VERSION ""

NS_ :

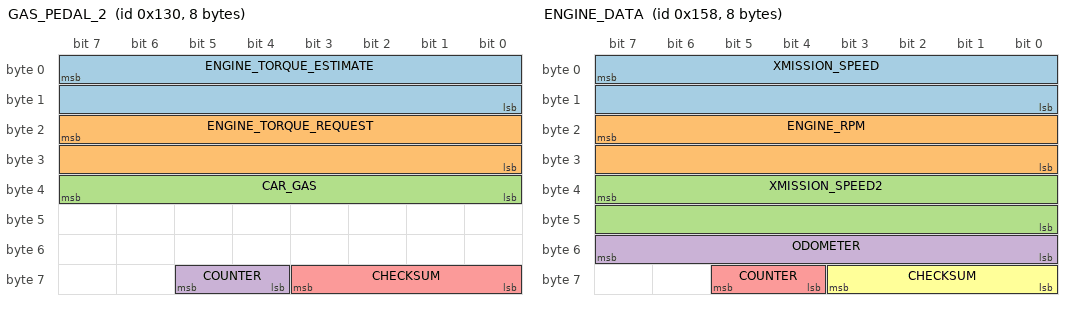
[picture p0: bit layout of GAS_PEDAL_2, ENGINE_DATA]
BO_ 304 GAS_PEDAL_2: 8 PCM
 SG_ ENGINE_TORQUE_ESTIMATE : 7|16@0- (1,0) [-1000|1000] "Nm" EON
 SG_ ENGINE_TORQUE_REQUEST : 23|16@0- (1,0) [-1000|1000] "Nm" EON
 SG_ CAR_GAS : 39|8@0+ (1,0) [0|255] "" EON
 SG_ COUNTER : 61|2@0+ (1,0) [0|3] "" EON
 SG_ CHECKSUM : 59|4@0+ (1,0) [0|15] "" EON

BO_ 316 GAS_PEDAL: 8 PCM
 SG_ CAR_GAS : 39|8@0+ (1,0) [0|255] "" EON
 SG_ COUNTER : 61|2@0+ (1,0) [0|3] "" EON
 SG_ CHECKSUM : 59|4@0+ (1,0) [0|15] "" EON

BO_ 344 ENGINE_DATA: 8 PCM
 SG_ XMISSION_SPEED : 7|16@0+ (0.01,0) [0|250] "kph" EON
 SG_ ENGINE_RPM : 23|16@0+ (1,0) [0|15000] "rpm" EON
 SG_ XMISSION_SPEED2 : 39|16@0+ (0.01,0) [0|250] "kph" EON
 SG_ ODOMETER : 55|8@0+ (10,0) [0|2550] "m" XXX
 SG_ COUNTER : 61|2@0+ (1,0) [0|3] "" EON
 SG_ CHECKSUM : 59|4@0+ (1,0) [0|15] "" EON

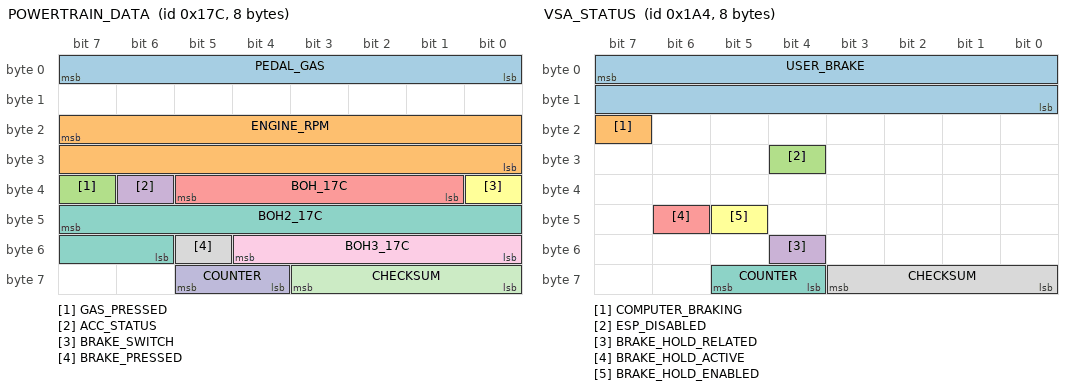
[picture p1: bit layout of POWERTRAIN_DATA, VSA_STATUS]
BO_ 380 POWERTRAIN_DATA: 8 PCM
 SG_ PEDAL_GAS : 7|8@0+ (1,0) [0|255] "" EON
 SG_ ENGINE_RPM : 23|16@0+ (1,0) [0|15000] "rpm" EON
 SG_ GAS_PRESSED : 39|1@0+ (1,0) [0|1] "" EON
 SG_ ACC_STATUS : 38|1@0+ (1,0) [0|1] "" EON
 SG_ BOH_17C : 37|5@0+ (1,0) [0|1] "" EON
 SG_ BRAKE_SWITCH : 32|1@0+ (1,0) [0|1] "" EON
 SG_ BOH2_17C : 47|10@0+ (1,0) [0|1] "" EON
 SG_ BRAKE_PRESSED : 53|1@0+ (1,0) [0|1] "" EON
 SG_ BOH3_17C : 52|5@0+ (1,0) [0|1] "" EON
 SG_ COUNTER : 61|2@0+ (1,0) [0|3] "" EON
 SG_ CHECKSUM : 59|4@0+ (1,0) [0|15] "" EON

BO_ 420 VSA_STATUS: 8 VSA
 SG_ USER_BRAKE : 7|16@0+ (0.015625,-1.609375) [0|1000] "" EON
 SG_ COMPUTER_BRAKING : 23|1@0+ (1,0) [0|1] "" EON
 SG_ ESP_DISABLED : 28|1@0+ (1,0) [0|1] "" EON
 SG_ BRAKE_HOLD_RELATED : 52|1@0+ (1,0) [0|1] "" XXX
 SG_ BRAKE_HOLD_ACTIVE : 46|1@0+ (1,0) [0|1] "" EON
 SG_ BRAKE_HOLD_ENABLED : 45|1@0+ (1,0) [0|1] "" EON
 SG_ COUNTER : 61|2@0+ (1,0) [0|3] "" EON
 SG_ CHECKSUM : 59|4@0+ (1,0) [0|15] "" EON

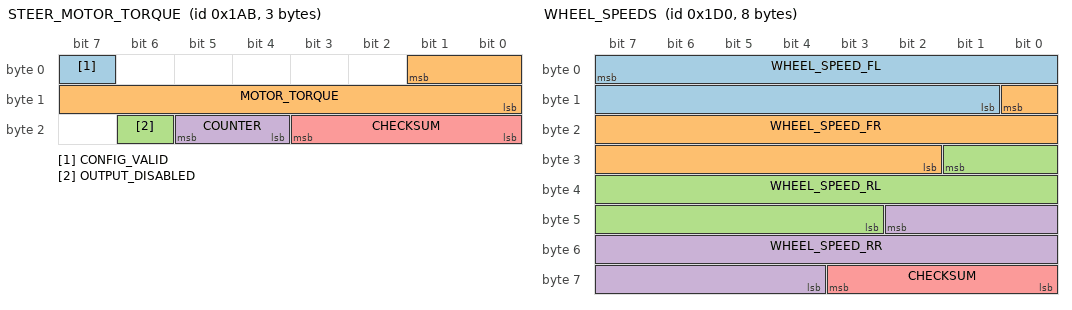
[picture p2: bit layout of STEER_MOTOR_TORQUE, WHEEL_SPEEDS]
BO_ 427 STEER_MOTOR_TORQUE: 3 EPS
 SG_ CONFIG_VALID : 7|1@0+ (1,0) [0|1] "" EON
 SG_ MOTOR_TORQUE : 1|10@0+ (1,0) [0|256] "" EON
 SG_ OUTPUT_DISABLED : 22|1@0+ (1,0) [0|1] "" EON
 SG_ COUNTER : 21|2@0+ (1,0) [0|3] "" EON
 SG_ CHECKSUM : 19|4@0+ (1,0) [0|15] "" EON

BO_ 464 WHEEL_SPEEDS: 8 VSA
 SG_ WHEEL_SPEED_FL : 7|15@0+ (0.01,0) [0|250] "kph" EON
 SG_ WHEEL_SPEED_FR : 8|15@0+ (0.01,0) [0|250] "kph" EON
 SG_ WHEEL_SPEED_RL : 25|15@0+ (0.01,0) [0|250] "kph" EON
 SG_ WHEEL_SPEED_RR : 42|15@0+ (0.01,0) [0|250] "kph" EON
 SG_ CHECKSUM : 59|4@0+ (1,0) [0|3] "" EON

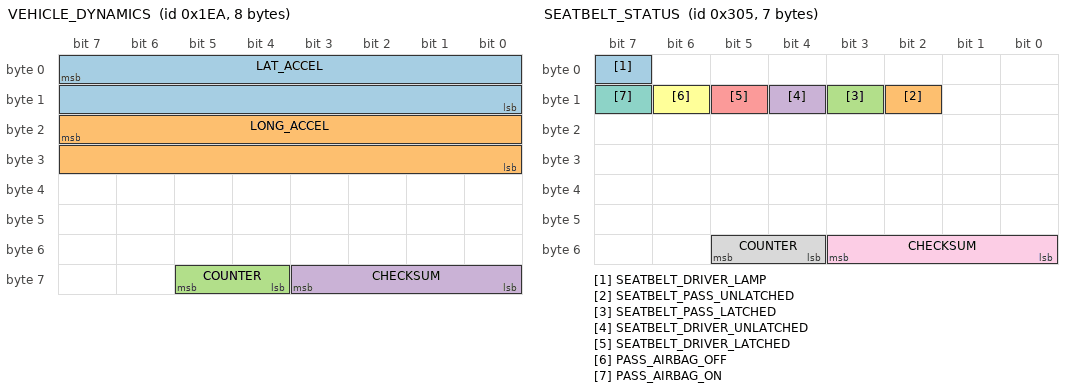
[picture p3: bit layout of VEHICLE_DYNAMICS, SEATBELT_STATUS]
BO_ 490 VEHICLE_DYNAMICS: 8 VSA
 SG_ LAT_ACCEL : 7|16@0- (0.0015,0) [-20|20] "m/s2" EON
 SG_ LONG_ACCEL : 23|16@0- (0.0015,0) [-20|20] "m/s2" EON
 SG_ COUNTER : 61|2@0+ (1,0) [0|3] "" EON
 SG_ CHECKSUM : 59|4@0+ (1,0) [0|3] "" EON

BO_ 773 SEATBELT_STATUS: 7 BDY
 SG_ SEATBELT_DRIVER_LAMP : 7|1@0+ (1,0) [0|1] "" EON
 SG_ SEATBELT_PASS_UNLATCHED : 10|1@0+ (1,0) [0|1] "" EON
 SG_ SEATBELT_PASS_LATCHED : 11|1@0+ (1,0) [0|1] "" EON
 SG_ SEATBELT_DRIVER_UNLATCHED : 12|1@0+ (1,0) [0|1] "" EON
 SG_ SEATBELT_DRIVER_LATCHED : 13|1@0+ (1,0) [0|1] "" EON
 SG_ PASS_AIRBAG_OFF : 14|1@0+ (1,0) [0|1] "" EON
 SG_ PASS_AIRBAG_ON : 15|1@0+ (1,0) [0|1] "" EON
 SG_ COUNTER : 53|2@0+ (1,0) [0|3] "" EON
 SG_ CHECKSUM : 51|4@0+ (1,0) [0|3] "" EON

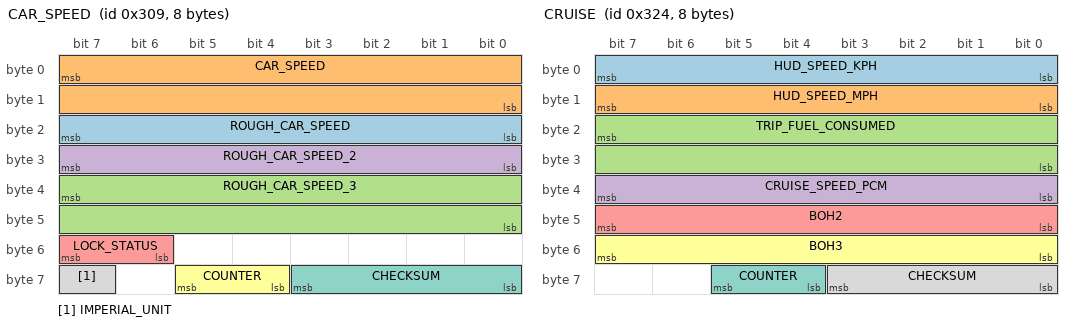
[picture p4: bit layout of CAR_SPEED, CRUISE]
BO_ 777 CAR_SPEED: 8 PCM
 SG_ ROUGH_CAR_SPEED : 23|8@0+ (1,0) [0|255] "mph" XXX
 SG_ CAR_SPEED : 7|16@0+ (0.01,0) [0|65535] "kph" XXX
 SG_ ROUGH_CAR_SPEED_3 : 39|16@0+ (0.01,0) [0|65535] "kph" XXX
 SG_ ROUGH_CAR_SPEED_2 : 31|8@0+ (1,0) [0|255] "mph" XXX
 SG_ LOCK_STATUS : 55|2@0+ (1,0) [0|255] "" XXX
 SG_ COUNTER : 61|2@0+ (1,0) [0|3] "" XXX
 SG_ CHECKSUM : 59|4@0+ (1,0) [0|15] "" XXX
 SG_ IMPERIAL_UNIT : 63|1@0+ (1,0) [0|1] "" XXX

BO_ 780 ACC_HUD: 8 ADAS
 SG_ PCM_SPEED : 7|16@0+ (0.01,0) [0|250] "kph" BDY
 SG_ PCM_GAS : 23|8@0+ (1,0) [0|127] "" BDY
 SG_ CRUISE_SPEED : 31|8@0+ (1,0) [0|255] "kph" BDY
 SG_ DTC_MODE : 39|1@0+ (1,0) [0|1] "" BDY
 SG_ BOH : 38|1@0+ (1,0) [0|1] "" BDY
 SG_ ACC_PROBLEM : 37|1@0+ (1,0) [0|1] "" BDY
 SG_ FCM_OFF : 35|1@0+ (1,0) [0|1] "" BDY
 SG_ FCM_OFF_2 : 36|1@0+ (1,0) [0|1] "" BDY
 SG_ FCM_PROBLEM : 34|1@0+ (1,0) [0|1] "" BDY
 SG_ RADAR_OBSTRUCTED : 33|1@0+ (1,0) [0|1] "" BDY
 SG_ ENABLE_MINI_CAR : 32|1@0+ (1,0) [0|1] "" BDY
 SG_ HUD_DISTANCE : 47|2@0+ (1,0) [0|3] "" BDY
 SG_ HUD_LEAD : 45|2@0+ (1,0) [0|3] "" BDY
 SG_ BOH_3 : 43|1@0+ (1,0) [0|3] "" BDY
 SG_ BOH_4 : 42|1@0+ (1,0) [0|3] "" BDY
 SG_ BOH_5 : 41|1@0+ (1,0) [0|3] "" BDY
 SG_ CRUISE_CONTROL_LABEL : 40|1@0+ (1,0) [0|3] "" BDY
 SG_ SET_ME_X01_2 : 55|1@0+ (1,0) [0|1] "" BDY
 SG_ IMPERIAL_UNIT : 54|1@0+ (1,0) [0|1] "" BDY
 SG_ ACC_ON : 52|1@0+ (1,0) [0|1] "" BDY
 SG_ CHIME : 51|3@0+ (1,0) [0|1] "" BDY
 SG_ SET_ME_X01 : 48|1@0+ (1,0) [0|1] "" BDY
 SG_ ICONS : 63|2@0+ (1,0) [0|1] "" BDY
 SG_ COUNTER : 61|2@0+ (1,0) [0|3] "" BDY
 SG_ CHECKSUM : 59|4@0+ (1,0) [0|3] "" BDY

BO_ 804 CRUISE: 8 PCM
 SG_ HUD_SPEED_KPH : 7|8@0+ (1,0) [0|255] "kph" EON
 SG_ HUD_SPEED_MPH : 15|8@0+ (1,0) [0|255] "mph" EON
 SG_ TRIP_FUEL_CONSUMED : 23|16@0+ (1,0) [0|255] "" EON
 SG_ CRUISE_SPEED_PCM : 39|8@0+ (1,0) [0|255] "" EON
 SG_ BOH2 : 47|8@0- (1,0) [0|255] "" EON
 SG_ BOH3 : 55|8@0+ (1,0) [0|255] "" EON
 SG_ COUNTER : 61|2@0+ (1,0) [0|3] "" EON
 SG_ CHECKSUM : 59|4@0+ (1,0) [0|15] "" EON

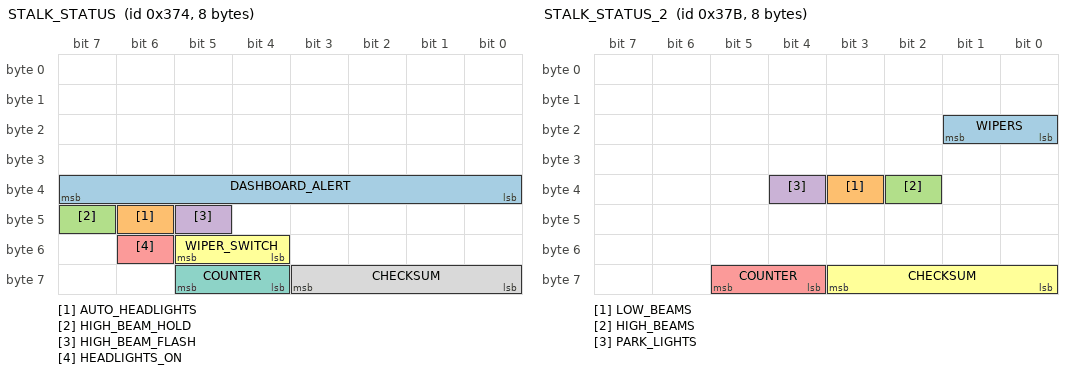
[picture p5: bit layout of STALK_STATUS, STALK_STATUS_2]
BO_ 884 STALK_STATUS: 8 XXX
 SG_ DASHBOARD_ALERT : 39|8@0+ (1,0) [0|255] "" EON
 SG_ AUTO_HEADLIGHTS : 46|1@0+ (1,0) [0|1] "" EON
 SG_ HIGH_BEAM_HOLD : 47|1@0+ (1,0) [0|1] "" EON
 SG_ HIGH_BEAM_FLASH : 45|1@0+ (1,0) [0|1] "" EON
 SG_ HEADLIGHTS_ON : 54|1@0+ (1,0) [0|1] "" EON
 SG_ WIPER_SWITCH : 53|2@0+ (1,0) [0|3] "" XXX
 SG_ COUNTER : 61|2@0+ (1,0) [0|3] "" EON
 SG_ CHECKSUM : 59|4@0+ (1,0) [0|15] "" EON

BO_ 891 STALK_STATUS_2: 8 XXX
 SG_ WIPERS : 17|2@0+ (1,0) [0|3] "" EON
 SG_ LOW_BEAMS : 35|1@0+ (1,0) [0|1] "" XXX
 SG_ HIGH_BEAMS : 34|1@0+ (1,0) [0|1] "" XXX
 SG_ PARK_LIGHTS : 36|1@0+ (1,0) [0|1] "" XXX
 SG_ COUNTER : 61|2@0+ (1,0) [0|3] "" EON
 SG_ CHECKSUM : 59|4@0+ (1,0) [0|15] "" EON

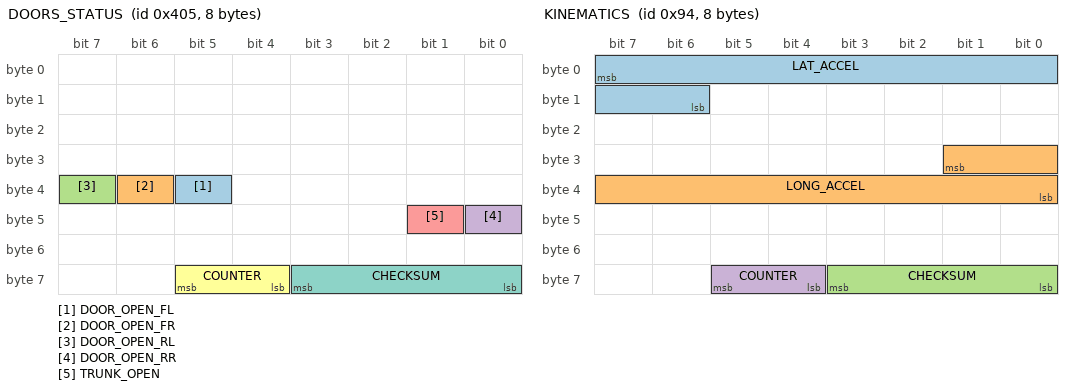
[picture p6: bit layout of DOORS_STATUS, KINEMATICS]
BO_ 1029 DOORS_STATUS: 8 BDY
 SG_ DOOR_OPEN_FL : 37|1@0+ (1,0) [0|1] "" EON
 SG_ DOOR_OPEN_FR : 38|1@0+ (1,0) [0|1] "" EON
 SG_ DOOR_OPEN_RL : 39|1@0+ (1,0) [0|1] "" EON
 SG_ DOOR_OPEN_RR : 40|1@0+ (1,0) [0|1] "" EON
 SG_ TRUNK_OPEN : 41|1@0+ (1,0) [0|1] "" EON
 SG_ COUNTER : 61|2@0+ (1,0) [0|3] "" EON
 SG_ CHECKSUM : 59|4@0+ (1,0) [0|15] "" EON

BO_ 148 KINEMATICS: 8 XXX
 SG_ LAT_ACCEL : 7|10@0+ (-0.035,17.92) [-20|20] "m/s2" EON
 SG_ LONG_ACCEL : 25|10@0+ (-0.035,17.92) [-20|20] "m/s2" EON
 SG_ CHECKSUM : 59|4@0+ (1,0) [0|3] "" EON
 SG_ COUNTER : 61|2@0+ (1,0) [0|3] "" EON

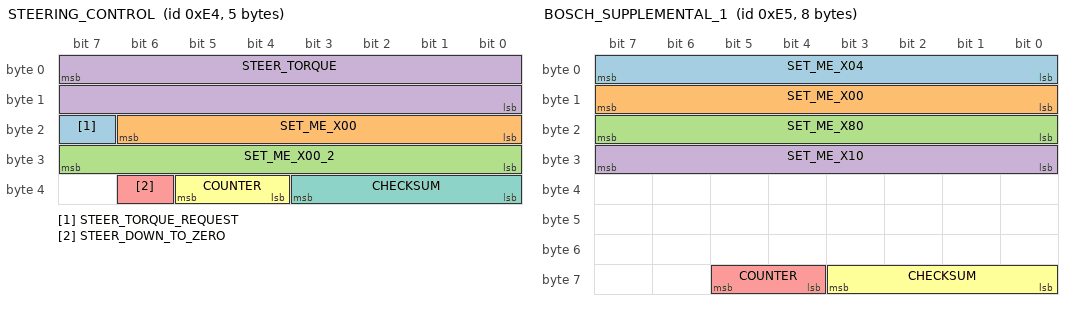
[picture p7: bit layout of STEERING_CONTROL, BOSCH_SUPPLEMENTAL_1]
BO_ 228 STEERING_CONTROL: 5 EON
 SG_ STEER_TORQUE_REQUEST : 23|1@0+ (1,0) [0|1] "" EPS
 SG_ SET_ME_X00 : 22|7@0+ (1,0) [0|127] "" EPS
 SG_ SET_ME_X00_2 : 31|8@0+ (1,0) [0|0] "" EPS
 SG_ STEER_TORQUE : 7|16@0- (1,0) [-4096|4096] "" EPS
 SG_ STEER_DOWN_TO_ZERO : 38|1@0+ (1,0) [0|1] "" EPS
 SG_ COUNTER : 37|2@0+ (1,0) [0|3] "" EPS
 SG_ CHECKSUM : 35|4@0+ (1,0) [0|15] "" EPS

BO_ 229 BOSCH_SUPPLEMENTAL_1: 8 XXX
 SG_ SET_ME_X04 : 0|8@1+ (1,0) [0|255] "" XXX
 SG_ SET_ME_X00 : 8|8@1+ (1,0) [0|255] "" XXX
 SG_ SET_ME_X80 : 16|8@1+ (1,0) [0|255] "" XXX
 SG_ SET_ME_X10 : 24|8@1+ (1,0) [0|255] "" XXX
 SG_ COUNTER : 61|2@0+ (1,0) [0|3] "" XXX
 SG_ CHECKSUM : 59|4@0+ (1,0) [0|15] "" XXX

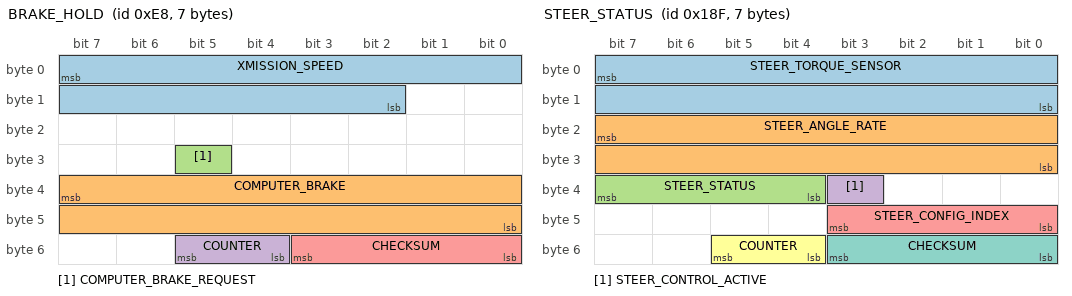
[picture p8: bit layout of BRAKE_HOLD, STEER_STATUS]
BO_ 232 BRAKE_HOLD: 7 XXX
 SG_ XMISSION_SPEED : 7|14@0- (1,0) [1|0] "" XXX
 SG_ COMPUTER_BRAKE : 39|16@0+ (1,0) [0|0] "" XXX
 SG_ COMPUTER_BRAKE_REQUEST : 29|1@0+ (1,0) [0|0] "" XXX
 SG_ COUNTER : 53|2@0+ (1,0) [0|3] "" XXX
 SG_ CHECKSUM : 51|4@0+ (1,0) [0|15] "" XXX

BO_ 399 STEER_STATUS: 7 EPS
 SG_ STEER_TORQUE_SENSOR : 7|16@0- (-1,0) [-31000|31000] "tbd" EON
 SG_ STEER_ANGLE_RATE : 23|16@0- (-0.1,0) [-31000|31000] "deg/s" EON
 SG_ STEER_STATUS : 39|4@0+ (1,0) [0|15] "" EON
 SG_ STEER_CONTROL_ACTIVE : 35|1@0+ (1,0) [0|1] "" EON
 SG_ STEER_CONFIG_INDEX : 43|4@0+ (1,0) [0|15] "" EON
 SG_ COUNTER : 53|2@0+ (1,0) [0|3] "" EON
 SG_ CHECKSUM : 51|4@0+ (1,0) [0|15] "" EON

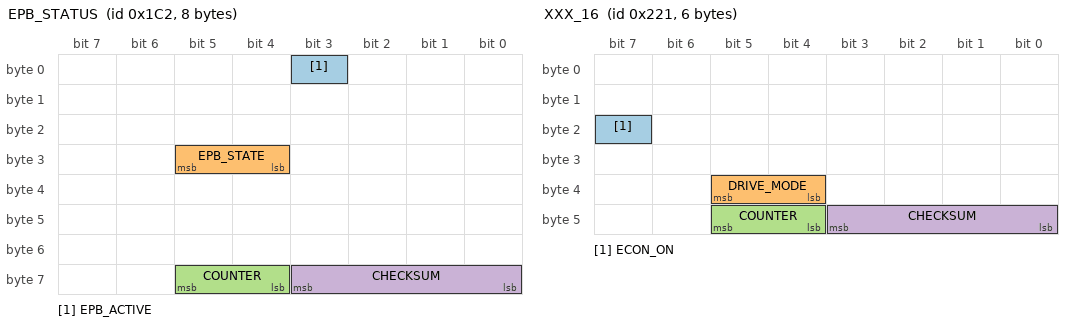
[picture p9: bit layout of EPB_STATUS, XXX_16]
BO_ 450 EPB_STATUS: 8 EPB
 SG_ EPB_ACTIVE : 3|1@0+ (1,0) [0|1] "" EON
 SG_ EPB_STATE : 29|2@0+ (1,0) [0|3] "" EON
 SG_ COUNTER : 61|2@0+ (1,0) [0|3] "" XXX
 SG_ CHECKSUM : 59|4@0+ (1,0) [0|15] "" XXX

BO_ 545 XXX_16: 6 SCM
 SG_ ECON_ON : 23|1@0+ (1,0) [0|1] "" XXX
 SG_ DRIVE_MODE : 37|2@0+ (1,0) [0|3] "" XXX
 SG_ COUNTER : 45|2@0+ (1,0) [0|3] "" BDY
 SG_ CHECKSUM : 43|4@0+ (1,0) [0|15] "" BDY

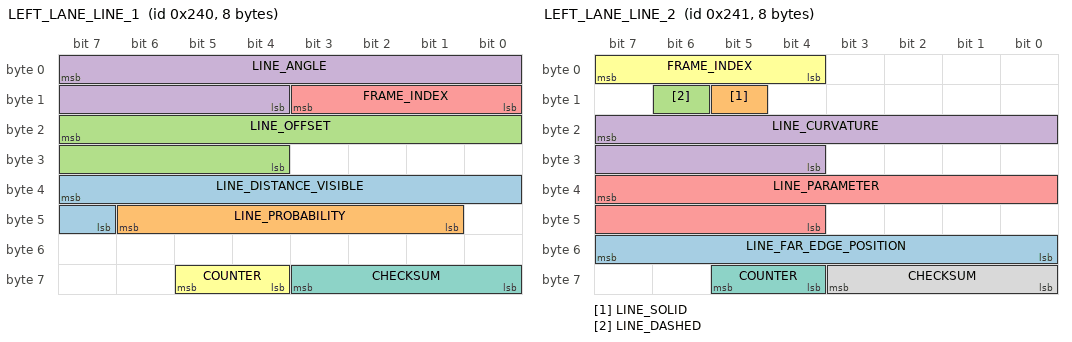
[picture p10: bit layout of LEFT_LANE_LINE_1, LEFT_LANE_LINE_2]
BO_ 576 LEFT_LANE_LINE_1: 8 CAM
 SG_ LINE_DISTANCE_VISIBLE : 39|9@0+ (1,0) [0|1] "" XXX
 SG_ LINE_PROBABILITY : 46|6@0+ (0.015625,0) [0|1] "" XXX
 SG_ LINE_OFFSET : 23|12@0+ (0.004,-8.192) [0|1] "Meters" XXX
 SG_ LINE_ANGLE : 7|12@0+ (0.0005,-1.024) [0|1] "" XXX
 SG_ FRAME_INDEX : 8|4@1+ (1,0) [0|15] "" XXX
 SG_ COUNTER : 61|2@0+ (1,0) [0|1] "" XXX
 SG_ CHECKSUM : 59|4@0+ (1,0) [0|1] "" XXX

BO_ 577 LEFT_LANE_LINE_2: 8 CAM
 SG_ LINE_FAR_EDGE_POSITION : 55|8@0+ (1,-128) [0|1] "" XXX
 SG_ LINE_SOLID : 13|1@0+ (1,0) [0|1] "" XXX
 SG_ LINE_DASHED : 14|1@0+ (1,0) [0|1] "" XXX
 SG_ LINE_CURVATURE : 23|12@0+ (0.00001,-0.02048) [0|1] "" XXX
 SG_ LINE_PARAMETER : 39|12@0+ (1,0) [0|1] "" XXX
 SG_ FRAME_INDEX : 7|4@0+ (1,0) [0|15] "" XXX
 SG_ COUNTER : 61|2@0+ (1,0) [0|1] "" XXX
 SG_ CHECKSUM : 59|4@0+ (1,0) [0|1] "" XXX

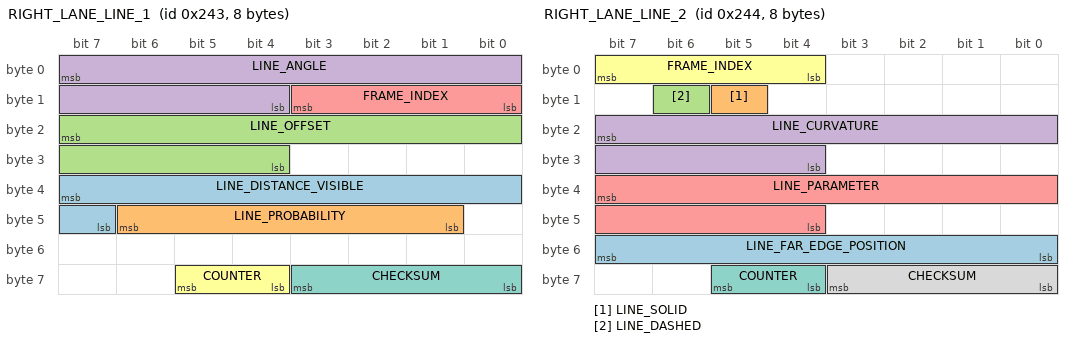
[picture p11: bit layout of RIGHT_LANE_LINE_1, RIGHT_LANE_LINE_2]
BO_ 579 RIGHT_LANE_LINE_1: 8 CAM
 SG_ LINE_DISTANCE_VISIBLE : 39|9@0+ (1,0) [0|1] "" XXX
 SG_ LINE_PROBABILITY : 46|6@0+ (0.015625,0) [0|1] "" XXX
 SG_ LINE_OFFSET : 23|12@0+ (0.004,-8.192) [0|1] "Meters" XXX
 SG_ LINE_ANGLE : 7|12@0+ (0.0005,-1.024) [0|1] "" XXX
 SG_ FRAME_INDEX : 8|4@1+ (1,0) [0|15] "" XXX
 SG_ COUNTER : 61|2@0+ (1,0) [0|1] "" XXX
 SG_ CHECKSUM : 59|4@0+ (1,0) [0|1] "" XXX

BO_ 580 RIGHT_LANE_LINE_2: 8 CAM
 SG_ LINE_FAR_EDGE_POSITION : 55|8@0+ (1,-128) [0|1] "" XXX
 SG_ LINE_SOLID : 13|1@0+ (1,0) [0|1] "" XXX
 SG_ LINE_DASHED : 14|1@0+ (1,0) [0|1] "" XXX
 SG_ LINE_CURVATURE : 23|12@0+ (0.00001,-0.02048) [0|1] "" XXX
 SG_ LINE_PARAMETER : 39|12@0+ (1,0) [0|1] "" XXX
 SG_ FRAME_INDEX : 7|4@0+ (1,0) [0|15] "" XXX
 SG_ COUNTER : 61|2@0+ (1,0) [0|1] "" XXX
 SG_ CHECKSUM : 59|4@0+ (1,0) [0|1] "" XXX

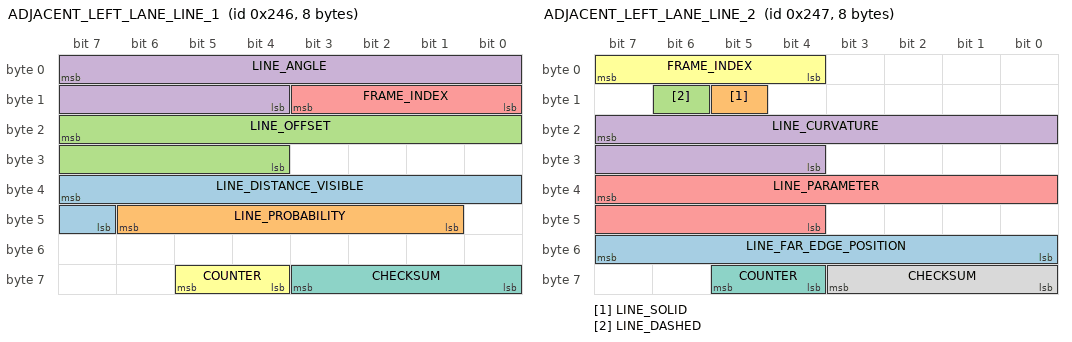
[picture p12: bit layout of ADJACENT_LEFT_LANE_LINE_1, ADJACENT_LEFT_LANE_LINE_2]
BO_ 582 ADJACENT_LEFT_LANE_LINE_1: 8 CAM
 SG_ LINE_DISTANCE_VISIBLE : 39|9@0+ (1,0) [0|1] "" XXX
 SG_ LINE_PROBABILITY : 46|6@0+ (0.015625,0) [0|1] "" XXX
 SG_ LINE_OFFSET : 23|12@0+ (0.004,-8.192) [0|1] "Meters" XXX
 SG_ LINE_ANGLE : 7|12@0+ (0.0005,-1.024) [0|1] "" XXX
 SG_ FRAME_INDEX : 8|4@1+ (1,0) [0|15] "" XXX
 SG_ COUNTER : 61|2@0+ (1,0) [0|1] "" XXX
 SG_ CHECKSUM : 59|4@0+ (1,0) [0|1] "" XXX

BO_ 583 ADJACENT_LEFT_LANE_LINE_2: 8 CAM
 SG_ LINE_FAR_EDGE_POSITION : 55|8@0+ (1,-128) [0|1] "" XXX
 SG_ LINE_SOLID : 13|1@0+ (1,0) [0|1] "" XXX
 SG_ LINE_DASHED : 14|1@0+ (1,0) [0|1] "" XXX
 SG_ LINE_CURVATURE : 23|12@0+ (0.00001,-0.02048) [0|1] "" XXX
 SG_ LINE_PARAMETER : 39|12@0+ (1,0) [0|1] "" XXX
 SG_ FRAME_INDEX : 7|4@0+ (1,0) [0|15] "" XXX
 SG_ COUNTER : 61|2@0+ (1,0) [0|1] "" XXX
 SG_ CHECKSUM : 59|4@0+ (1,0) [0|1] "" XXX

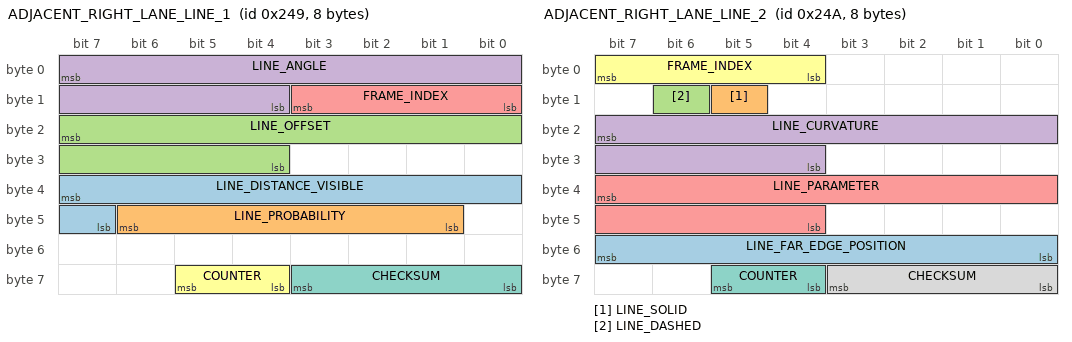
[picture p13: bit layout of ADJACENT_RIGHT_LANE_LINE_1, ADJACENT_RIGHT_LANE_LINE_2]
BO_ 585 ADJACENT_RIGHT_LANE_LINE_1: 8 CAM
 SG_ LINE_DISTANCE_VISIBLE : 39|9@0+ (1,0) [0|1] "" XXX
 SG_ LINE_PROBABILITY : 46|6@0+ (0.015625,0) [0|1] "" XXX
 SG_ LINE_OFFSET : 23|12@0+ (0.004,-8.192) [0|1] "Meters" XXX
 SG_ LINE_ANGLE : 7|12@0+ (0.0005,-1.024) [0|1] "" XXX
 SG_ FRAME_INDEX : 8|4@1+ (1,0) [0|15] "" XXX
 SG_ COUNTER : 61|2@0+ (1,0) [0|1] "" XXX
 SG_ CHECKSUM : 59|4@0+ (1,0) [0|1] "" XXX

BO_ 586 ADJACENT_RIGHT_LANE_LINE_2: 8 CAM
 SG_ LINE_FAR_EDGE_POSITION : 55|8@0+ (1,-128) [0|1] "" XXX
 SG_ LINE_SOLID : 13|1@0+ (1,0) [0|1] "" XXX
 SG_ LINE_DASHED : 14|1@0+ (1,0) [0|1] "" XXX
 SG_ LINE_CURVATURE : 23|12@0+ (0.00001,-0.02048) [0|1] "" XXX
 SG_ LINE_PARAMETER : 39|12@0+ (1,0) [0|1] "" XXX
 SG_ FRAME_INDEX : 7|4@0+ (1,0) [0|15] "" XXX
 SG_ COUNTER : 61|2@0+ (1,0) [0|1] "" XXX
 SG_ CHECKSUM : 59|4@0+ (1,0) [0|1] "" XXX

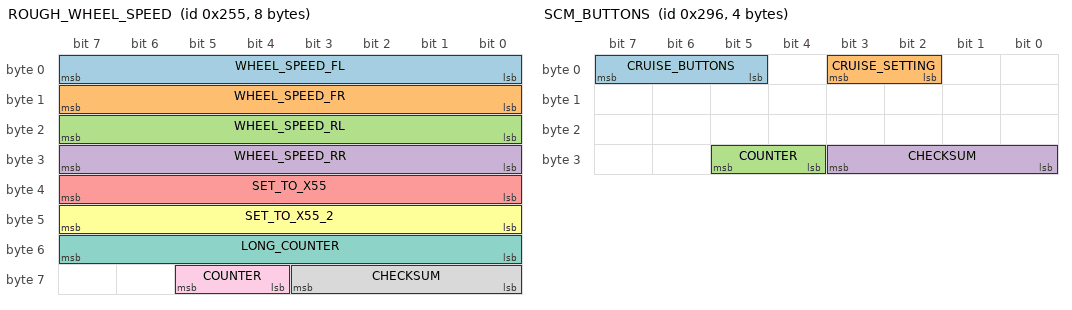
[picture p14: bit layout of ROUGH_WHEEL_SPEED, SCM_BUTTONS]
BO_ 597 ROUGH_WHEEL_SPEED: 8 VSA
 SG_ WHEEL_SPEED_FL : 7|8@0+ (1,0) [0|255] "mph" EON
 SG_ WHEEL_SPEED_FR : 15|8@0+ (1,0) [0|255] "mph" EON
 SG_ WHEEL_SPEED_RL : 23|8@0+ (1,0) [0|255] "mph" EON
 SG_ WHEEL_SPEED_RR : 31|8@0+ (1,0) [0|255] "mph" EON
 SG_ SET_TO_X55 : 39|8@0+ (1,0) [0|255] "" XXX
 SG_ SET_TO_X55_2 : 47|8@0+ (1,0) [0|255] "" EON
 SG_ LONG_COUNTER : 55|8@0+ (1,0) [0|255] "" XXX
 SG_ CHECKSUM : 59|4@0+ (1,0) [0|15] "" XXX
 SG_ COUNTER : 61|2@0+ (1,0) [0|3] "" XXX

BO_ 662 SCM_BUTTONS: 4 SCM
 SG_ CRUISE_BUTTONS : 7|3@0+ (1,0) [0|7] "" EON
 SG_ CRUISE_SETTING : 3|2@0+ (1,0) [0|3] "" EON
 SG_ COUNTER : 29|2@0+ (1,0) [0|3] "" EON
 SG_ CHECKSUM : 27|4@0+ (1,0) [0|15] "" EON

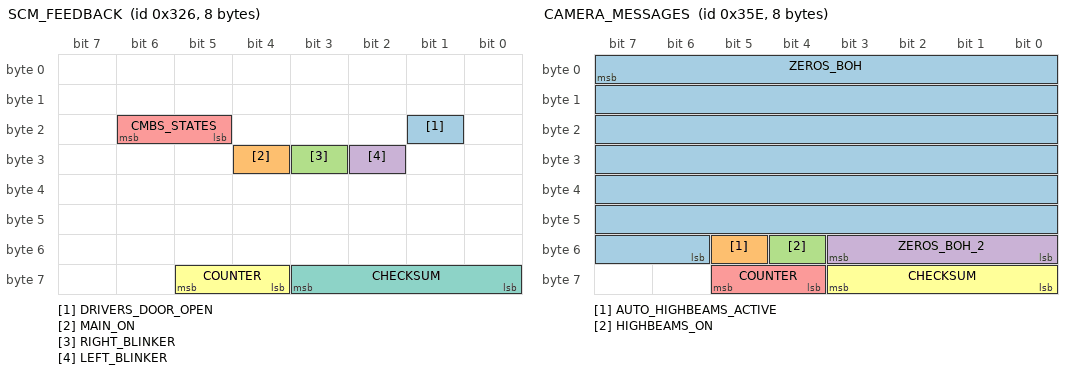
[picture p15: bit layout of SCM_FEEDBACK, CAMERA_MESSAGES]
BO_ 806 SCM_FEEDBACK: 8 SCM
 SG_ DRIVERS_DOOR_OPEN : 17|1@0+ (1,0) [0|1] "" XXX
 SG_ MAIN_ON : 28|1@0+ (1,0) [0|1] "" EON
 SG_ RIGHT_BLINKER : 27|1@0+ (1,0) [0|1] "" EON
 SG_ LEFT_BLINKER : 26|1@0+ (1,0) [0|1] "" EON
 SG_ CMBS_STATES : 22|2@0+ (1,0) [0|3] "" EON
 SG_ COUNTER : 61|2@0+ (1,0) [0|3] "" XXX
 SG_ CHECKSUM : 59|4@0+ (1,0) [0|15] "" XXX

BO_ 862 CAMERA_MESSAGES: 8 CAM
 SG_ ZEROS_BOH : 7|50@0+ (1,0) [0|127] "" BDY
 SG_ AUTO_HIGHBEAMS_ACTIVE : 53|1@0+ (1,0) [0|1] "" XXX
 SG_ HIGHBEAMS_ON : 52|1@0+ (1,0) [0|1] "" XXX
 SG_ ZEROS_BOH_2 : 51|4@0+ (1,0) [0|15] "" XXX
 SG_ COUNTER : 61|2@0+ (1,0) [0|3] "" XXX
 SG_ CHECKSUM : 59|4@0+ (1,0) [0|15] "" XXX

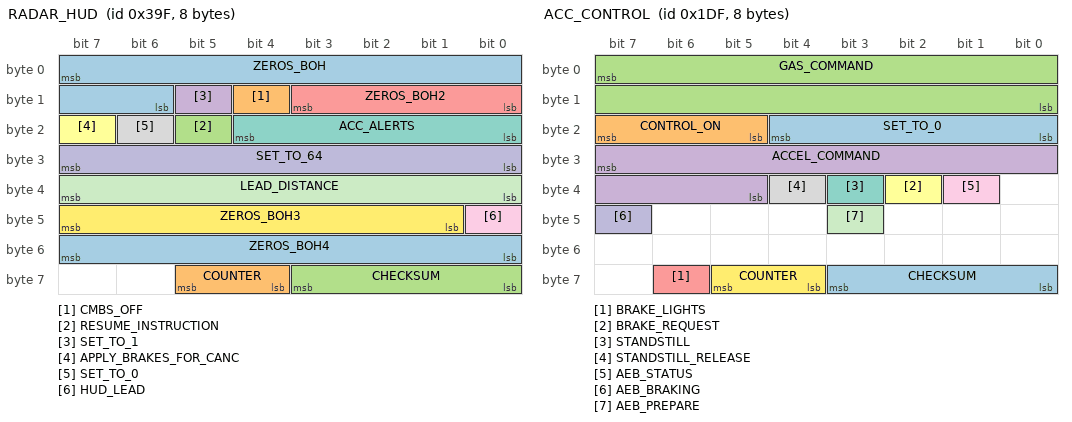
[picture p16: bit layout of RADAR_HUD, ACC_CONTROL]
BO_ 927 RADAR_HUD: 8 RADAR
 SG_ ZEROS_BOH : 7|10@0+ (1,0) [0|127] "" BDY
 SG_ CMBS_OFF : 12|1@0+ (1,0) [0|1] "" BDY
 SG_ RESUME_INSTRUCTION : 21|1@0+ (1,0) [0|1] "" XXX
 SG_ SET_TO_1 : 13|1@0+ (1,0) [0|1] "" BDY
 SG_ ZEROS_BOH2 : 11|4@0+ (1,0) [0|1] "" XXX
 SG_ APPLY_BRAKES_FOR_CANC : 23|1@0+ (1,0) [0|1] "" XXX
 SG_ ACC_ALERTS : 20|5@0+ (1,0) [0|1] "" BDY
 SG_ SET_TO_0 : 22|1@0+ (1,0) [0|1] "" XXX
 SG_ HUD_LEAD : 40|1@0+ (1,0) [0|1] "" XXX
 SG_ SET_TO_64 : 31|8@0+ (1,0) [0|255] "" XXX
 SG_ LEAD_DISTANCE : 39|8@0+ (1,0) [0|255] "" XXX
 SG_ ZEROS_BOH3 : 47|7@0+ (1,0) [0|127] "" XXX
 SG_ ZEROS_BOH4 : 55|8@0+ (1,0) [0|255] "" XXX
 SG_ COUNTER : 61|2@0+ (1,0) [0|3] "" XXX
 SG_ CHECKSUM : 59|4@0+ (1,0) [0|15] "" XXX

BO_ 13274 LKAS_HUD_A: 5 ADAS
 SG_ CAM_TEMP_HIGH : 7|1@0+ (1,0) [0|255] "" BDY
 SG_ SET_ME_X41 : 6|7@0+ (1,0) [0|127] "" BDY
 SG_ BOH : 6|7@0+ (1,0) [0|127] "" BDY
 SG_ DASHED_LANES : 14|1@0+ (1,0) [0|1] "" BDY
 SG_ DTC : 13|1@0+ (1,0) [0|1] "" BDY
 SG_ LKAS_PROBLEM : 12|1@0+ (1,0) [0|1] "" BDY
 SG_ LKAS_OFF : 11|1@0+ (1,0) [0|1] "" BDY
 SG_ SOLID_LANES : 10|1@0+ (1,0) [0|1] "" BDY
 SG_ LDW_RIGHT : 9|1@0+ (1,0) [0|1] "" BDY
 SG_ STEERING_REQUIRED : 8|1@0+ (1,0) [0|1] "" BDY
 SG_ BOH_2 : 23|2@0+ (1,0) [0|4] "" BDY
 SG_ LDW_PROBLEM : 21|1@0+ (1,0) [0|1] "" BDY
 SG_ BEEP : 17|2@0+ (1,0) [0|1] "" BDY
 SG_ SET_ME_X01 : 20|1@0+ (1,0) [0|1] "" BDY
 SG_ LDW_ON : 28|1@0+ (1,0) [0|1] "" BDY
 SG_ LDW_OFF : 27|1@0+ (1,0) [0|1] "" BDY
 SG_ CLEAN_WINDSHIELD : 26|1@0+ (1,0) [0|1] "" BDY
 SG_ COUNTER : 37|2@0+ (1,0) [0|3] "" BDY
 SG_ CHECKSUM : 35|4@0+ (1,0) [0|15] "" BDY

BO_ 13275 LKAS_HUD_B: 8 ADAS
 SG_ CAM_TEMP_HIGH : 7|1@0+ (1,0) [0|255] "" BDY
 SG_ SET_ME_X41 : 6|7@0+ (1,0) [0|127] "" BDY
 SG_ BOH : 6|7@0+ (1,0) [0|127] "" BDY
 SG_ DASHED_LANES : 14|1@0+ (1,0) [0|1] "" BDY
 SG_ DTC : 13|1@0+ (1,0) [0|1] "" BDY
 SG_ LKAS_PROBLEM : 12|1@0+ (1,0) [0|1] "" BDY
 SG_ LKAS_OFF : 11|1@0+ (1,0) [0|1] "" BDY
 SG_ SOLID_LANES : 10|1@0+ (1,0) [0|1] "" BDY
 SG_ LDW_RIGHT : 9|1@0+ (1,0) [0|1] "" BDY
 SG_ STEERING_REQUIRED : 8|1@0+ (1,0) [0|1] "" BDY
 SG_ BOH_2 : 23|2@0+ (1,0) [0|4] "" BDY
 SG_ LDW_PROBLEM : 21|1@0+ (1,0) [0|1] "" BDY
 SG_ BEEP : 17|2@0+ (1,0) [0|1] "" BDY
 SG_ SET_ME_X01 : 20|1@0+ (1,0) [0|1] "" BDY
 SG_ LDW_ON : 28|1@0+ (1,0) [0|1] "" BDY
 SG_ LDW_OFF : 27|1@0+ (1,0) [0|1] "" BDY
 SG_ CLEAN_WINDSHIELD : 26|1@0+ (1,0) [0|1] "" BDY
 SG_ COUNTER : 61|2@0+ (1,0) [0|3] "" BDY
 SG_ CHECKSUM : 59|4@0+ (1,0) [0|15] "" BDY

BO_ 479 ACC_CONTROL: 8 EON
 SG_ SET_TO_0 : 20|5@0+ (1,0) [0|1] "" XXX
 SG_ CONTROL_ON : 23|3@0+ (1,0) [0|5] "" XXX
 SG_ GAS_COMMAND : 7|16@0- (1,0) [0|0] "" XXX
 SG_ ACCEL_COMMAND : 31|11@0- (0.01,0) [0|0] "m/s2" XXX
 SG_ BRAKE_LIGHTS : 62|1@0+ (1,0) [0|1] "" XXX
 SG_ BRAKE_REQUEST : 34|1@0+ (1,0) [0|1] "" XXX
 SG_ STANDSTILL : 35|1@0+ (1,0) [0|1] "" XXX
 SG_ STANDSTILL_RELEASE : 36|1@0+ (1,0) [0|1] "" XXX
 SG_ AEB_STATUS : 33|1@0+ (1,0) [0|1] "" XXX
 SG_ AEB_BRAKING : 47|1@0+ (1,0) [0|1] "" XXX
 SG_ AEB_PREPARE : 43|1@0+ (1,0) [0|1] "" XXX
 SG_ COUNTER : 61|2@0+ (1,0) [0|3] "" XXX
 SG_ CHECKSUM : 59|4@0+ (1,0) [0|15] "" XXX

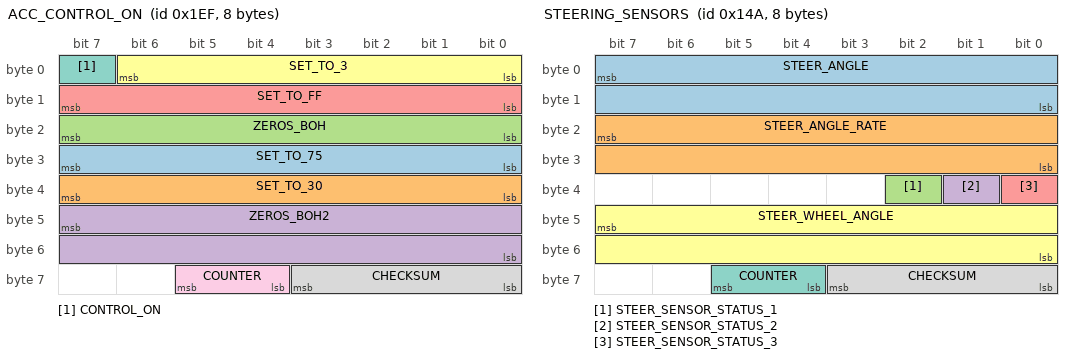
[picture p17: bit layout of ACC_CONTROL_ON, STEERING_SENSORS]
BO_ 495 ACC_CONTROL_ON: 8 XXX
 SG_ SET_TO_75 : 31|8@0+ (1,0) [0|255] "" XXX
 SG_ SET_TO_30 : 39|8@0+ (1,0) [0|255] "" XXX
 SG_ ZEROS_BOH : 23|8@0+ (1,0) [0|255] "" XXX
 SG_ ZEROS_BOH2 : 47|16@0+ (1,0) [0|255] "" XXX
 SG_ SET_TO_FF : 15|8@0+ (1,0) [0|255] "" XXX
 SG_ SET_TO_3 : 6|7@0+ (1,0) [0|4095] "" XXX
 SG_ CONTROL_ON : 7|1@0+ (1,0) [0|1] "" XXX
 SG_ CHECKSUM : 59|4@0+ (1,0) [0|15] "" XXX
 SG_ COUNTER : 61|2@0+ (1,0) [0|3] "" XXX

BO_ 829 LKAS_HUD: 5 ADAS
 SG_ CAM_TEMP_HIGH : 7|1@0+ (1,0) [0|255] "" BDY
 SG_ SET_ME_X41 : 6|7@0+ (1,0) [0|127] "" BDY
 SG_ BOH : 6|7@0+ (1,0) [0|127] "" BDY
 SG_ DASHED_LANES : 14|1@0+ (1,0) [0|1] "" BDY
 SG_ DTC : 13|1@0+ (1,0) [0|1] "" BDY
 SG_ LKAS_PROBLEM : 12|1@0+ (1,0) [0|1] "" BDY
 SG_ LKAS_OFF : 11|1@0+ (1,0) [0|1] "" BDY
 SG_ SOLID_LANES : 10|1@0+ (1,0) [0|1] "" BDY
 SG_ LDW_RIGHT : 9|1@0+ (1,0) [0|1] "" BDY
 SG_ STEERING_REQUIRED : 8|1@0+ (1,0) [0|1] "" BDY
 SG_ BOH_2 : 23|2@0+ (1,0) [0|4] "" BDY
 SG_ LDW_PROBLEM : 21|1@0+ (1,0) [0|1] "" BDY
 SG_ BEEP : 17|2@0+ (1,0) [0|1] "" BDY
 SG_ LDW_ON : 28|1@0+ (1,0) [0|1] "" BDY
 SG_ LDW_OFF : 27|1@0+ (1,0) [0|1] "" BDY
 SG_ CLEAN_WINDSHIELD : 26|1@0+ (1,0) [0|1] "" BDY
 SG_ SET_ME_X48 : 31|8@0+ (1,0) [0|255] "" BDY
 SG_ COUNTER : 37|2@0+ (1,0) [0|3] "" BDY
 SG_ CHECKSUM : 35|4@0+ (1,0) [0|15] "" BDY

BO_ 330 STEERING_SENSORS: 8 EPS
 SG_ STEER_ANGLE : 7|16@0- (-0.1,0) [-500|500] "deg" EON
 SG_ STEER_ANGLE_RATE : 23|16@0- (-1,0) [-3000|3000] "deg/s" EON
 SG_ STEER_SENSOR_STATUS_1 : 34|1@0+ (1,0) [0|1] "" EON
 SG_ STEER_SENSOR_STATUS_2 : 33|1@0+ (1,0) [0|1] "" EON
 SG_ STEER_SENSOR_STATUS_3 : 32|1@0+ (1,0) [0|1] "" EON
 SG_ STEER_WHEEL_ANGLE : 47|16@0- (-0.1,0) [-500|500] "deg" EON
 SG_ COUNTER : 61|2@0+ (1,0) [0|3] "" EON
 SG_ CHECKSUM : 59|4@0+ (1,0) [0|15] "" EON

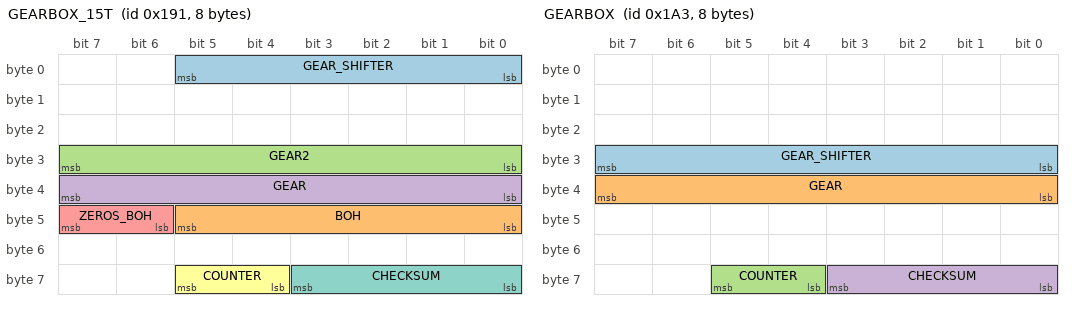
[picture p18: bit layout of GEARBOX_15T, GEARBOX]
BO_ 401 GEARBOX_15T: 8 PCM
 SG_ GEAR_SHIFTER : 5|6@0+ (1,0) [0|63] "" EON
 SG_ BOH : 45|6@0+ (1,0) [0|63] "" XXX
 SG_ GEAR2 : 31|8@0+ (1,0) [0|1] "" XXX
 SG_ GEAR : 39|8@0+ (1,0) [0|255] "" XXX
 SG_ ZEROS_BOH : 47|2@0+ (1,0) [0|3] "" XXX
 SG_ COUNTER : 61|2@0+ (1,0) [0|3] "" EON
 SG_ CHECKSUM : 59|4@0+ (1,0) [0|15] "" EON

BO_ 419 GEARBOX: 8 XXX
 SG_ GEAR_SHIFTER : 24|8@1+ (1,0) [0|255] "" XXX
 SG_ GEAR : 32|8@1+ (1,0) [0|255] "" XXX
 SG_ COUNTER : 61|2@0+ (1,0) [0|3] "" XXX
 SG_ CHECKSUM : 59|4@0+ (1,0) [0|15] "" XXX

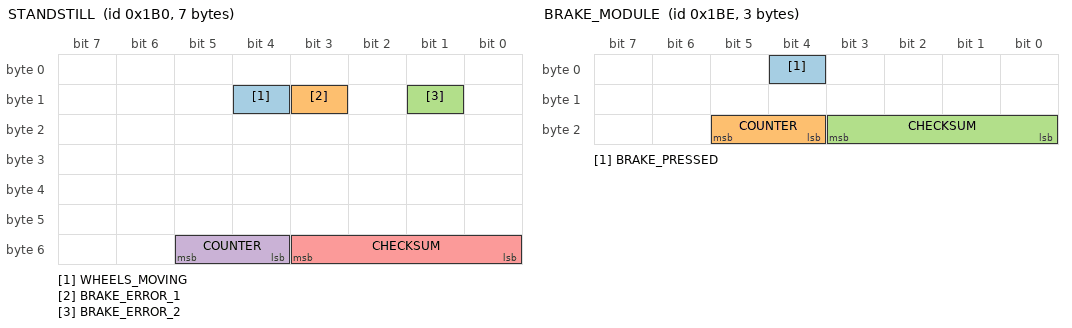
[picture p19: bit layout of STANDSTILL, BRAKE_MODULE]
BO_ 432 STANDSTILL: 7 VSA
 SG_ WHEELS_MOVING : 12|1@0+ (1,0) [0|1] "" EON
 SG_ BRAKE_ERROR_1 : 11|1@0+ (1,0) [0|1] "" EON
 SG_ BRAKE_ERROR_2 : 9|1@0+ (1,0) [0|1] "" EON
 SG_ COUNTER : 53|2@0+ (1,0) [0|3] "" EON
 SG_ CHECKSUM : 51|4@0+ (1,0) [0|15] "" EON

BO_ 446 BRAKE_MODULE: 3 VSA
 SG_ BRAKE_PRESSED : 4|1@0+ (1,0) [0|1] "" XXX
 SG_ COUNTER : 21|2@0+ (1,0) [0|3] "" XXX
 SG_ CHECKSUM : 19|4@0+ (1,0) [0|15] "" XXX

BO_ 506 LEGACY_BRAKE_COMMAND: 8 ADAS
 SG_ CHIME : 40|8@1+ (1,0) [0|255] "" XXX
 SG_ CHECKSUM : 59|4@0+ (1,0) [0|15] "" XXX
 SG_ COUNTER : 61|2@0+ (1,0) [0|3] "" XXX

BO_ 892 CRUISE_PARAMS: 8 PCM
 SG_ CRUISE_SPEED_OFFSET : 31|8@0- (0.1,0) [-128|127] "kph" EON
 SG_ CHECKSUM : 59|4@0+ (1,0) [0|3] "" EON
 SG_ COUNTER : 61|2@0+ (1,0) [0|15] "" EON

BO_ 1302 ODOMETER: 8 XXX
 SG_ ODOMETER : 7|24@0+ (1,0) [0|16777215] "km" EON
 SG_ COUNTER : 61|2@0+ (1,0) [0|3] "" EON
 SG_ CHECKSUM : 59|4@0+ (1,0) [0|3] "" EON

BU_: Airbag_MQB BAP_Tester_MQB BMS_MQB Datenlogger_MQB Gateway_MQB Getriebe_DQ_Hybrid_MQB Getriebe_DQ_MQB LEH_MQB Motor_Diesel_MQB Motor_Hybrid_MQB Motor_Otto_MQB SAK_MQB Waehlhebel_MQB Vector__XXX l c i XXX

CM_ "AUTOGENERATED FILE, DO NOT EDIT";

CM_ "Imported file _stellantis_common.dbc starts here";
CM_ SG_ 258 STEERING_ANGLE_HP "Steering angle high precision";
CM_ SG_ 264 ENGINE_TORQUE "Effective engine torque";
CM_ SG_ 264 EXPECTED_ENGINE_TORQUE "Expected Engine Torque based on target engine speed";
CM_ SG_ 678 LKAS_ICON_COLOR "3 is yellow, 2 is green, 1 is white, 0 is null";
CM_ SG_ 678 LKAS_LANE_LINES "0x01 transparent lines, 0x02 left white, 0x03 right white, 0x04 left yellow with car on top, 0x05 left yellow with car on top, 0x06 both white, 0x07 left yellow, 0x08 left yellow right white, 0x09 right yellow, 0x0a right yellow left white, 0x0b left yellow with car on top right white, 0x0c right yellow with car on top left white, (0x00, 0x0d, 0x0e, 0x0f) null";
CM_ SG_ 678 LKAS_ALERTS "(0x01, 0x02) lane sense off, (0x03, 0x04, 0x06) place hands on steering wheel, 0x07 lane departure detected + place hands on steering wheel, (0x08, 0x09) lane sense unavailable + clean front windshield, 0x0b lane sense and auto high beam unavailable + clean front windshield, 0x0c lane sense unavailable + service required, (0x00, 0x05, 0x0a, 0x0d, 0x0e, 0x0f) null";

CM_ "chrysler_pacifica_2017_hybrid.dbc starts here";

CM_ SG_ 653 BRAKE_PRESSURE "max seems to be 148";
CM_ SG_ 746 PRNDL "5=L, 4=D, 3=N, 2=R, 1=P";
CM_ SG_ 320 BRAKE_PRESSED_2 "Value is 5 when brake is pressed by human, 1 when ACC brake";
CM_ SG_ 320 BRAKE_PRESSED_ACC "set when ACC brakes";
CM_ SG_ 792 TURN_SIGNALS "1=Left, 2=Right";
CM_ SG_ 264 ACCEL_PEDAL "not in ACC so seems to be actual pedal. Use for gasPressed";
CM_ SG_ 544 LKAS_STATE "2 when autopark has control, 8 when is actuatable by lkas, 4 when there is a fault";
CM_ SG_ 658 LKAS_STEERING_TORQUE "Most sent by stock system is 1024+-230. + is left. typically changes by 2 or 3 each 0.01s";
CM_ SG_ 678 LKAS_ICON_COLOR "3 is yellow, 2 is green, 1 is white, 0 is null";
CM_ SG_ 678 LKAS_LANE_LINES "0x01 transparent lines, 0x02 left white, 0x03 right white, 0x04 left yellow with car on top, 0x05 left yellow with car on top, 0x06 both white, 0x07 left yellow, 0x08 left yellow right white, 0x09 right yellow, 0x0a right yellow left white, 0x0b left yellow with car on top right white, 0x0c right yellow with car on top left white, (0x00, 0x0d, 0x0e, 0x0f) null";
CM_ SG_ 678 LKAS_ALERTS "(0x01, 0x02) lane sense off, (0x03, 0x04, 0x06) place hands on steering wheel, 0x07 lane departure detected + place hands on steering wheel, (0x08, 0x09) lane sense unavailable + clean front windshield, 0x0b lane sense and auto high beam unavailable + clean front windshield, 0x0c lane sense unavailable + service required, (0x00, 0x05, 0x0a, 0x0d, 0x0e, 0x0f) null";
CM_ SG_ 705 AUTO_PARK_TOGGLE_1 "set briefly when turning on or off self-parking";
CM_ SG_ 671 AUTO_PARK_CMD "Request Appears to be in NM";
CM_ SG_ 671 AUTO_PARK_STATUS "1 = IDLE / NO REQUEST 9 = START REQUEST 10 = REQUEST MODE 11 = REQUEST MODE";
CM_ SG_ 826 AUTO_PARK_GEAR_1 "Reverse=0, Forward=f";
CM_ SG_ 826 AUTO_PARK_GEAR_2 "Reverse=0, Forward=f";
CM_ SG_ 826 AUTO_PARK_GEAR_3 "Reverse=0, Forward=f";
CM_ SG_ 332 STEER_ANGLE_2 "slightly lags the other steer_angle signal. also more noisy.";
CM_ SG_ 608 PARKSENSE_DISABLED "set if parksense is disabled";
CM_ SG_ 729 LKAS_STATUS_OK "Set to 0x0820 when LKAS system is plugged in.";
CM_ SG_ 825 BEEP_339 "sent every 0.5s. 0050 is no beep. To beep send 4355 or 4155. Used by ParkSense warning.";
CM_ SG_ 270 ELECTRIC_MOTOR "0x7fff indicates electric motor not in use";
CM_ SG_ 291 ENERGY_GAIN_LOSS "unsure what this actually is";
CM_ SG_ 291 ENERGY_SMOOTHER_CURVE "unsure what it is, but smoother";
CM_ SG_ 308 ACCEL_134 "only set when human presses accel pedal";
CM_ SG_ 532 NOISY_SLOWLY_DECREASING "perhaps battery but do not know";
CM_ SG_ 816 TRACTION_OFF "set when traction off button is enabled";
CM_ SG_ 816 TOGGLE_PARKSENSE "sending 3000071ec0ff9000 enables or disables parksense";
CM_ SG_ 324 SPEED_2 "signal is approx half other speeds";
CM_ SG_ 501 ACC_SPEED_CONFIG_KPH "speed configured for ACC";
CM_ SG_ 501 ACC_SPEED_CONFIG_MPH "speed configured for ACC";
CM_ SG_ 501 CRUISE_STATE "may just be an icon, but seems to indicate different cruise modes: ACC and Non-ACC and engaged state for both.";
CM_ SG_ 625 SPEED "zero on non-acc drives";
